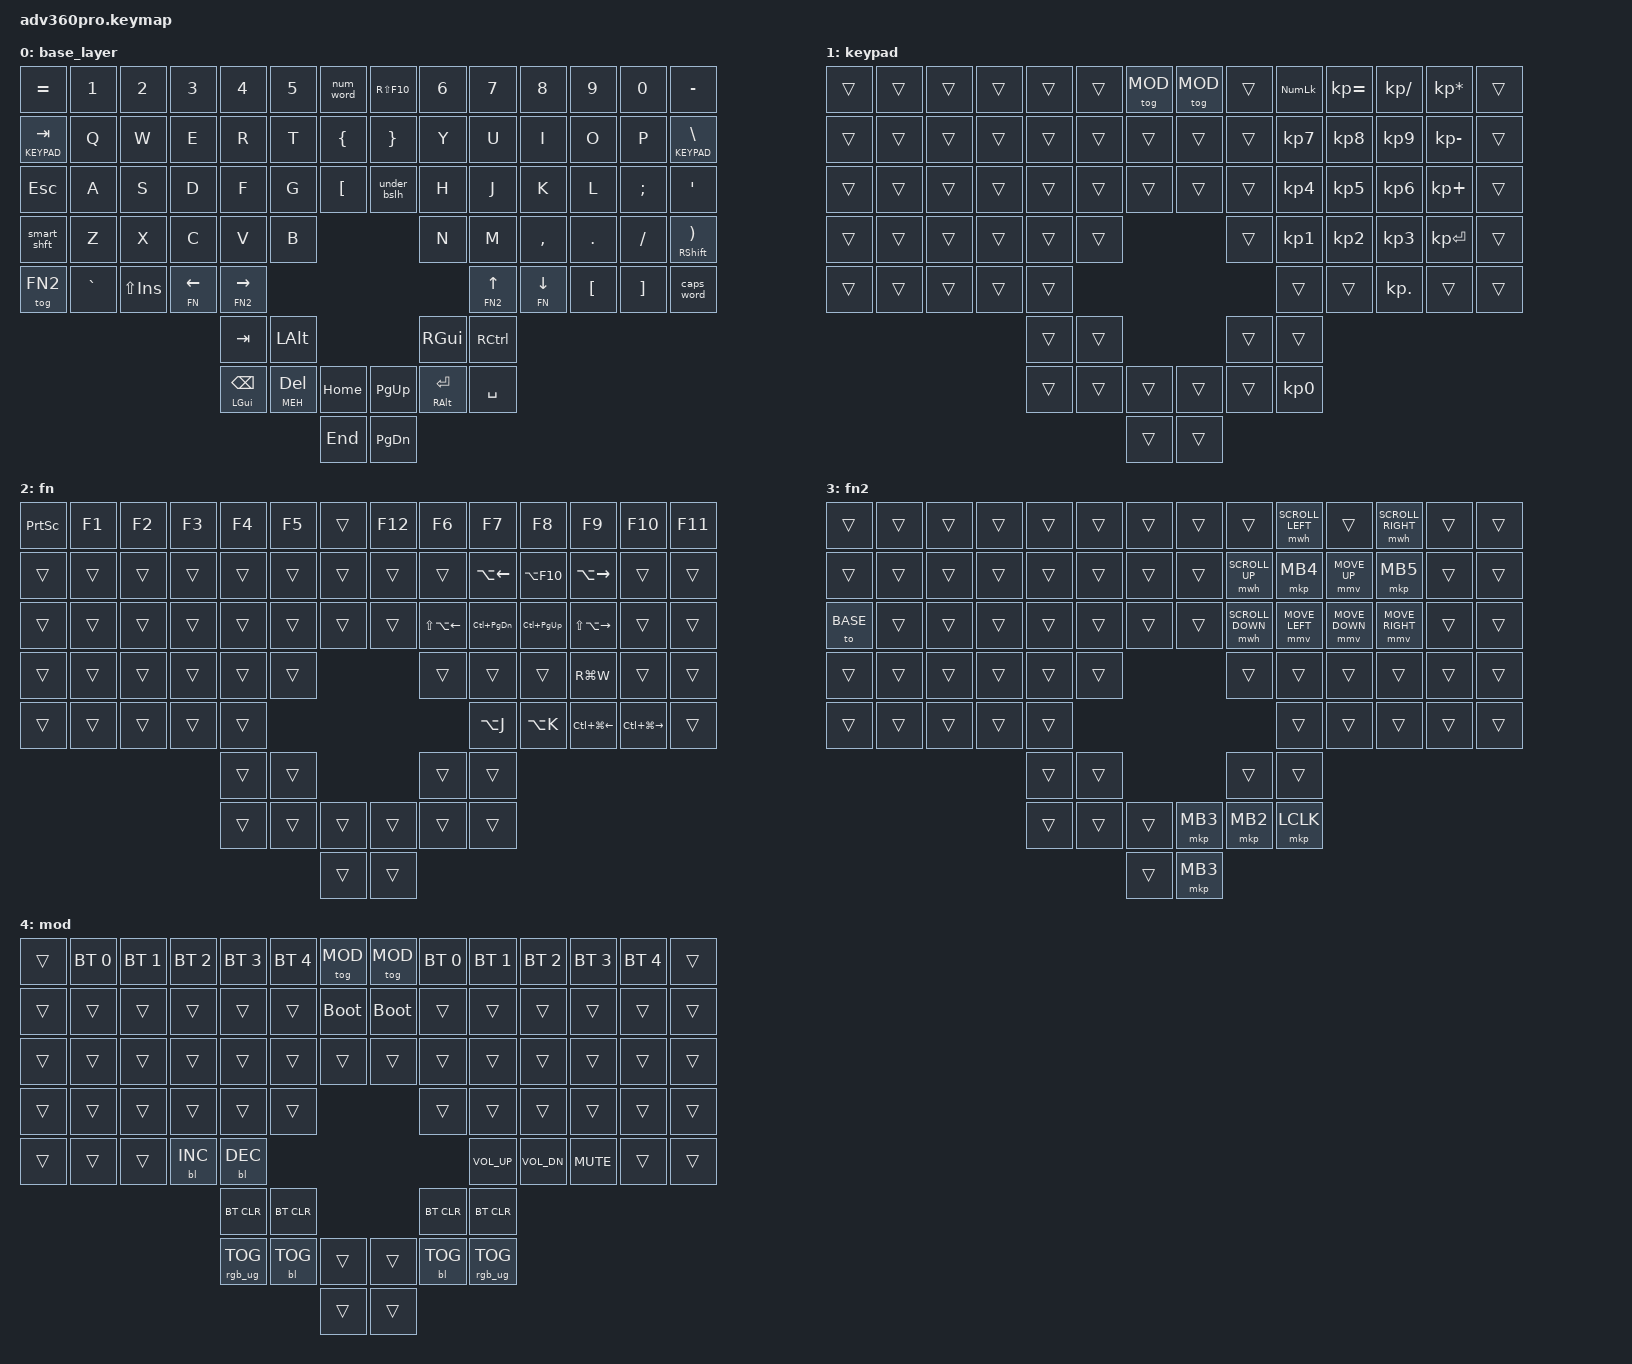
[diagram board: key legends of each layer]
#include <behaviors.dtsi>
#include <dt-bindings/zmk/keys.h>
#include <dt-bindings/zmk/bt.h>
#include <dt-bindings/zmk/outputs.h>
#include <dt-bindings/zmk/rgb.h>
#include <dt-bindings/zmk/backlight.h>
#include <dt-bindings/zmk/mouse.h>

#define ___ &trans
#define HYP LS(LC(LA(LGUI)))
#define MEH LC(LA(LGUI))

/* Layers */
#define BASE 0
#define KEYPAD 1
#define FN 2
#define FN2 3
#define MOD 4


/* Mouse settings /*
/*Both mouse movement and scrolling have independently configurable acceleration profiles with three parameters: delay before movement, time to max speed and the acceleration exponent.
//The exponent is usually set to 0 for constant speed, 1 for uniform acceleration or 2 for uniform jerk. */

#define MOVE_UP MOVE_VERT(-1600)
#define MOVE_DOWN MOVE_VERT(1600)
#define MOVE_LEFT MOVE_HOR(-1600)
#define MOVE_RIGHT MOVE_HOR(1600)

&mmv {
    time-to-max-speed-ms = <250>;
    acceleration-exponent = <1>;
};

#define SCROLL_UP SCROLL_VERT(13)
#define SCROLL_DOWN SCROLL_VERT(-13)
#define SCROLL_LEFT SCROLL_HOR(-13)
#define SCROLL_RIGHT SCROLL_HOR(13)

&mwh {
    time-to-max-speed-ms = <180>;
    acceleration-exponent = <1>;
};

&lt {
       tapping-term-ms = <300>;
       quick-tap-ms = <400>;
};

&mt {
       tapping-term-ms = <250>;
       quick-tap-ms = <350>;
};

/ {
    /* remove unused keys from layout and move thumb cluster to bottom */
    chosen {
        zmk,matrix_transform = &urobs_transform;
    };

    behaviors {
        mqt: mod_quick_tap {
        compatible = "zmk,behavior-hold-tap";
        label = "ZM_qt_mt";
        #binding-cells = <2>;
        flavor = "hold-preferred";
        tapping-term-ms = <225>;
        quick-tap-ms = <300>;
        bindings = <&kp>, <&kp>;
        };

        smart_shft: smart_shift {
            compatible = "zmk,behavior-mod-morph";
            label = "SMART_SHIFT";
            #binding-cells = <0>;
            bindings = <&mt LSHFT LPAR>, <&caps_word>;
            mods = <(MOD_RSFT)>;
        };

        under_bslh: underscore_backslach {
            compatible = "zmk,behavior-mod-morph";
            label = "UNDER_BKSLSH";
            #binding-cells = <0>;
            bindings = <&kp UNDER>, <&kp PIPE>;
            mods = <(MOD_LSFT|MOD_RSFT)>;
        };
    };

    keymap {
        compatible = "zmk,keymap";

    base_layer {
        bindings = <
&kp EQUAL	&kp N1	&kp N2	&kp N3	&kp N4	&kp N5	&num_word	&kp RS(F10)	&kp N6	&kp N7	&kp N8	&kp N9	&kp N0	&kp MINUS
&lt KEYPAD TAB	&kp Q	&kp W	&kp E	&kp R	&kp T	&kp LBRC	&kp RBRC	&kp Y	&kp U	&kp I	&kp O	&kp P	&lt KEYPAD BSLH
&kp ESC	&kp A	&kp S	&kp D	&kp F	&kp G	&kp LBKT	&under_bslh	&kp H	&kp J	&kp K	&kp L	&kp SEMI	&kp SQT
&smart_shft	&kp Z	&kp X	&kp C	&kp V	&kp B			&kp N	&kp M	&kp COMMA	&kp DOT	&kp FSLH	&mt RSHFT RPAR
&tog FN2	&kp GRAVE	&kp LS(INS)	&lt FN LEFT	&lt FN2 RIGHT					&lt FN2 UP	&lt FN DOWN	&kp LBKT	&kp RBKT	&caps_word
				&kp TAB	        &kp LALT				&kp RGUI	&kp RCTRL
				&mqt LGUI BSPC	&mqt MEH DEL	&kp HOME	&kp PG_UP	&mqt RALT RET	&kp SPACE
						                &kp END	        &kp PG_DN
        >;
    };

        keypad {
            bindings = <
                ___             ___       ___       ___              ___       ___       &tog MOD       &tog MOD  ___       &kp KP_NUM &kp KP_EQUAL &kp KP_DIVIDE &kp KP_MULTIPLY ___
                ___             ___       ___       ___              ___       ___       ___            ___       ___       &kp KP_N7  &kp KP_N8    &kp KP_N9     &kp KP_MINUS    ___
                ___             ___       ___       ___              ___       ___       ___            ___       ___       &kp KP_N4  &kp KP_N5    &kp KP_N6     &kp KP_PLUS     ___
                ___             ___       ___       ___              ___       ___                                ___       &kp KP_N1  &kp KP_N2    &kp KP_N3     &kp KP_ENTER    ___
                ___             ___       ___       ___              ___                                                    ___        ___          &kp KP_DOT    ___             ___
                                                                     ___       ___                                ___       ___
                                                                     ___       ___       ___            ___       ___       &kp KP_N0
                                                                                         ___            ___
            >;
        };

        fn {
            bindings = <
                &kp PSCRN       &kp F1    &kp F2    &kp F3           &kp F4   &kp F5     ___            &kp F12   &kp F6    &kp F7    &kp F8     &kp F9      &kp F10   &kp F11
                ___             ___       ___       ___              ___       ___       ___            ___       ___       &kp LA(LEFT)  &kp LA(F10)     &kp LA(RIGHT)       ___       ___
                ___             ___       ___       ___              ___       ___       ___            ___       &kp LS(LA(LEFT)) &kp LC(PG_DN) &kp LC(PG_UP)   &kp LS(LA(RIGHT)) ___       ___
                ___             ___       ___       ___              ___       ___                                ___       ___       ___         &kp RG(W)   ___       ___
                ___             ___       ___       ___              ___                                          &kp LA(J) &kp LA(K)        &kp LC(LG(LEFT))  &kp LC(LG(RIGHT))       ___
                                                                     ___       ___                                ___       ___
                                                                     ___       ___       ___            ___       ___       ___
                                                                                         ___            ___
            >;
        };

        fn2 {
            bindings = <
                ___             ___       ___       ___              ___       ___       ___            ___       ___              &mwh SCROLL_LEFT ___            &mwh SCROLL_RIGHT ___       ___
                ___             ___       ___       ___              ___       ___       ___            ___       &mwh SCROLL_UP   &mkp MB4         &mmv MOVE_UP   &mkp MB5          ___       ___
                &to BASE        ___       ___       ___              ___       ___       ___            ___       &mwh SCROLL_DOWN &mmv MOVE_LEFT   &mmv MOVE_DOWN &mmv MOVE_RIGHT   ___       ___
                ___             ___       ___       ___              ___       ___                                ___              ___              ___            ___               ___       ___
                ___             ___       ___       ___              ___                                                           ___              ___            ___               ___       ___

                                                                     ___       ___                                ___              ___
                                                                     ___       ___       ___            &mkp MB3  &mkp MB2         &mkp LCLK
                                                                                         ___            &mkp MB3
            >;
        };

        mod {
            bindings = <
                ___             &bt BT_SEL 0 &bt BT_SEL 1 &bt BT_SEL 2 &bt BT_SEL 3    &bt BT_SEL 4 &tog MOD         &tog MOD    &bt BT_SEL 0 &bt BT_SEL 1     &bt BT_SEL 2 &bt BT_SEL 3 &bt BT_SEL 4 ___
                ___             ___          ___          ___          ___             ___          &bootloader      &bootloader ___          ___              ___          ___          ___          ___
                ___             ___          ___          ___          ___             ___          ___              ___         ___          ___              ___          ___          ___          ___
                ___             ___          ___          ___          ___             ___                                       ___          ___              ___          ___          ___          ___
                ___             ___          ___          &bl BL_INC   &bl BL_DEC                                                             &kp C_VOL_UP     &kp C_VOL_DN &kp C_MUTE   ___          ___
                                                                     &bt BT_CLR      &bt BT_CLR                                &bt BT_CLR   &bt BT_CLR
                                                                     &rgb_ug RGB_TOG &bl BL_TOG   ___              ___         &bl BL_TOG   &rgb_ug RGB_TOG
                                                                                                  ___              ___
            >;
        };

    };

};


/*

        blank {
            bindings = <
                ___             ___       ___       ___              ___       ___       ___            ___       ___       ___       ___       ___       ___       ___
                ___             ___       ___       ___              ___       ___       ___            ___       ___       ___       ___       ___       ___       ___
                ___             ___       ___       ___              ___       ___       ___            ___       ___       ___       ___       ___       ___       ___
                ___             ___       ___       ___              ___       ___       ___            ___       ___       ___       ___       ___       ___       ___
                ___             ___       ___       ___              ___       ___                                ___       ___       ___       ___       ___       ___
                ___             ___       ___       ___              ___                                                    ___       ___       ___       ___       ___
                                                                     ___       ___                                ___       ___
                                                                     ___       ___       ___            ___       ___       ___
                                                                                         ___            ___
            >;
        };

*/
